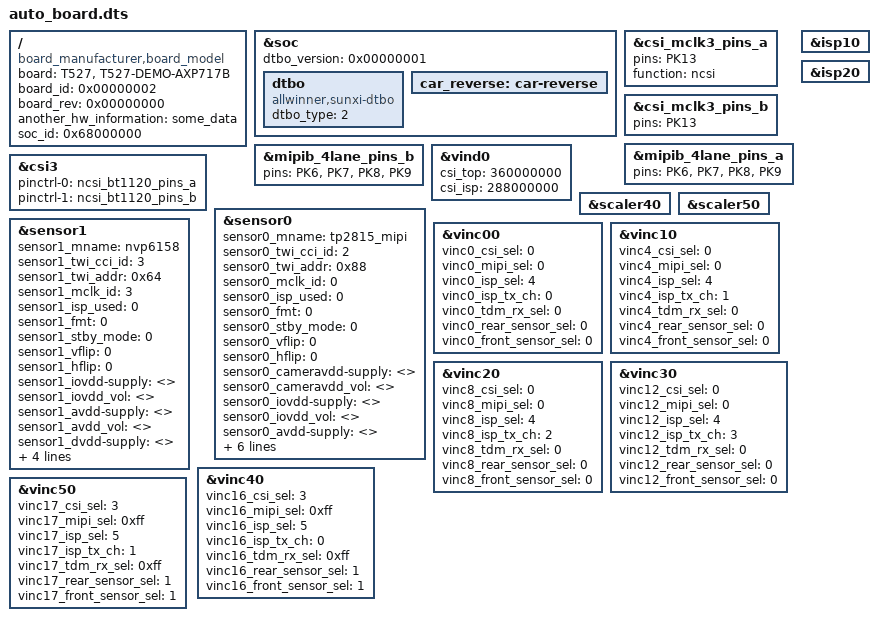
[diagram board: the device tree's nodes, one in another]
/dts-v1/;
/plugin/;
/ {
  /* As DTS design, these properties only for loader, won't overlay */
  compatible = "board_manufacturer,board_model";

  /* These properties are examples */
  board = "T527", "T527-DEMO-AXP717B";
  board_id = <0x00000002>;
  board_rev = <0x00000000>;
  another_hw_information = "some_data";
  soc_id = <0x68000000>;

};

&soc {
	dtbo_version = <0x00000001>;
	dtbo{
		compatible = "allwinner,sunxi-dtbo";
		dtbo_type = <2>;
	};
	car_reverse: car-reverse {
		status = "okay";
	};
};

&csi_mclk3_pins_a {
	pins = "PK13";
	function = "ncsi";
};

&csi_mclk3_pins_b {
	pins = "PK13";
};

&mipib_4lane_pins_a {
   pins = "PK6", "PK7", "PK8",
                        "PK9";
};

&mipib_4lane_pins_b {
   pins = "PK6", "PK7", "PK8",
                        "PK9";
};

&vind0 {
	csi_top = <360000000>;
	csi_isp = <288000000>;
};

&csi3 {
	pinctrl-0 = <&ncsi_bt1120_pins_a>;
	pinctrl-1 = <&ncsi_bt1120_pins_b>;
	status = "okay";
};

&isp10 {
	status = "okay";
};

&isp20 {
	status = "okay";
};

&scaler40 {
	status = "okay";
};

&scaler50 {
	status = "okay";
};

&sensor0 {
		sensor0_mname = "tp2815_mipi";
		sensor0_twi_cci_id = <2>;
		sensor0_twi_addr = <0x88>;
		sensor0_mclk_id = <0>;
		sensor0_isp_used = <0>;
		sensor0_fmt = <0>;
		sensor0_stby_mode = <0>;
		sensor0_vflip = <0>;
		sensor0_hflip = <0>;
		sensor0_cameravdd-supply = <>;
		sensor0_cameravdd_vol = <>;
		sensor0_iovdd-supply = <>;
		sensor0_iovdd_vol = <>;
		sensor0_avdd-supply = <>;
		sensor0_avdd_vol = <>;
		sensor0_dvdd-supply = <>;
		sensor0_dvdd_vol = <>;
		sensor0_power_en = <>;
		sensor0_reset = <&pio 10 11 0>;
		sensor0_pwdn = <>;
		status = "okay";
};

&sensor1 {
		sensor1_mname = "nvp6158";
		sensor1_twi_cci_id = <3>;
		sensor1_twi_addr = <0x64>;
		sensor1_mclk_id = <3>;
		sensor1_isp_used = <0>;
		sensor1_fmt = <0>;
		sensor1_stby_mode = <0>;
		sensor1_vflip = <0>;
		sensor1_hflip = <0>;
		sensor1_iovdd-supply = <>;
		sensor1_iovdd_vol = <>;
		sensor1_avdd-supply = <>;
		sensor1_avdd_vol = <>;
		sensor1_dvdd-supply = <>;
		sensor1_dvdd_vol = <>;
		sensor1_power_en = <>;
		sensor1_reset = <&pio 10 10 0>;
		sensor1_pwdn = <>;
		status = "okay";
};

&vinc00 {
	vinc0_csi_sel = <0>;
	vinc0_mipi_sel = <0>;
	vinc0_isp_sel = <4>;
	vinc0_isp_tx_ch = <0>;
	vinc0_tdm_rx_sel = <0>;
	vinc0_rear_sensor_sel = <0>;
	vinc0_front_sensor_sel = <0>;
	status = "okay";
};

&vinc10 {
	vinc4_csi_sel = <0>;
	vinc4_mipi_sel = <0>;
	vinc4_isp_sel = <4>;
	vinc4_isp_tx_ch = <1>;
	vinc4_tdm_rx_sel = <0>;
	vinc4_rear_sensor_sel = <0>;
	vinc4_front_sensor_sel = <0>;
	status = "okay";
};

&vinc20 {
        vinc8_csi_sel = <0>;
        vinc8_mipi_sel = <0>;
        vinc8_isp_sel = <4>;
        vinc8_isp_tx_ch = <2>;
        vinc8_tdm_rx_sel = <0>;
        vinc8_rear_sensor_sel = <0>;
        vinc8_front_sensor_sel = <0>;
	status = "okay";
};

&vinc30 {
        vinc12_csi_sel = <0>;
        vinc12_mipi_sel = <0>;
        vinc12_isp_sel = <4>;
        vinc12_isp_tx_ch = <3>;
        vinc12_tdm_rx_sel = <0>;
        vinc12_rear_sensor_sel = <0>;
        vinc12_front_sensor_sel = <0>;
	status = "okay";
};

&vinc40 {
        vinc16_csi_sel = <3>;
        vinc16_mipi_sel = <0xff>;
        vinc16_isp_sel = <5>;
        vinc16_isp_tx_ch = <0>;
        vinc16_tdm_rx_sel = <0xff>;
        vinc16_rear_sensor_sel = <1>;
        vinc16_front_sensor_sel = <1>;
	status = "okay";
};

&vinc50 {
        vinc17_csi_sel = <3>;
        vinc17_mipi_sel = <0xff>;
        vinc17_isp_sel = <5>;
        vinc17_isp_tx_ch = <1>;
        vinc17_tdm_rx_sel = <0xff>;
        vinc17_rear_sensor_sel = <1>;
        vinc17_front_sensor_sel = <1>;
	status = "okay";
};
